# DSIG register map
Registers from a debugger description file.
Registers are 32-bit, read-only, no defined reset value unless marked. A register's access mark holds for its fields unless they carry their own. Addresses are absolute; registers are grouped by the start of their names; lines under a group give offsets from that group; [hi:lo] are bit positions; {n}, {i} and the like mark numbered series; 'fields as' and 'values as' point back to an identical list; <NAME> marks a mode.

## MUXTRIG
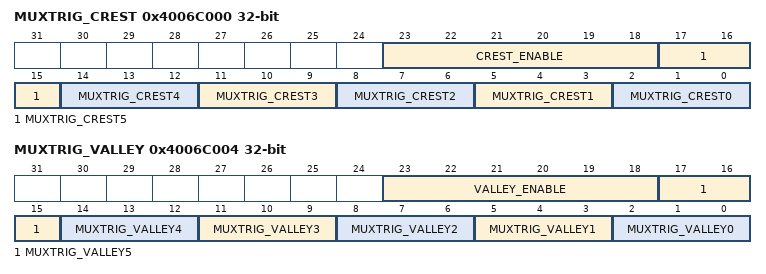
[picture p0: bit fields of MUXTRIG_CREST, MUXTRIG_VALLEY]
0x4006C000 MUXTRIG_CREST access not given
  [23:18] CREST_ENABLE, [3n+2:3n] MUXTRIG_CREST{n} (n=0..5)
0x4006C004 MUXTRIG_VALLEY access not given
  [23:18] VALLEY_ENABLE, [3n+2:3n] MUXTRIG_VALLEY{n} (n=0..5)

## CTRL
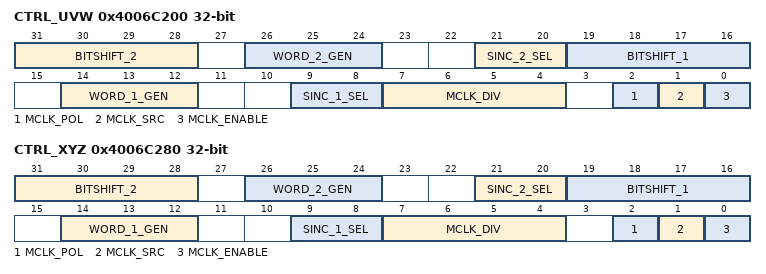
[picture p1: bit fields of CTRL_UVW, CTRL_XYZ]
0x4006C200 CTRL_UVW access not given
  [31:28] BITSHIFT_2, [26:24] WORD_2_GEN, [21:20] SINC_2_SEL, [19:16] BITSHIFT_1, [14:12] WORD_1_GEN, [9:8] SINC_1_SEL, [7:4] MCLK_DIV, [2] MCLK_POL, [1] MCLK_SRC, [0] MCLK_ENABLE
0x4006C280 CTRL_XYZ access not given
  fields as CTRL_UVW

## STATUS
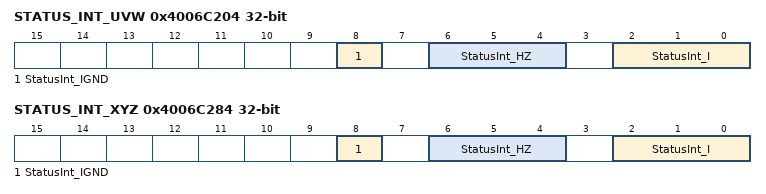
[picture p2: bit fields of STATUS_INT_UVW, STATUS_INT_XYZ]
0x4006C204 STATUS_INT_UVW access not given
  [8] StatusInt_IGND, [6:4] StatusInt_HZ, [2:0] StatusInt_I
0x4006C284 STATUS_INT_XYZ access not given
  [8] StatusInt_IGND, [6:4] StatusInt_HZ, [2:0] StatusInt_I

## CMP
0x4006C208 CMP_UVW_I_Under access not given
  [15:0] CMP_I_Under
0x4006C20C CMP_UVW_I_Over access not given
  [15:0] CMP_I_Over
0x4006C210 CMP_UVW_HZ_Under access not given
  [12:0] CMP_HZ_Under
0x4006C214 CMP_UVW_HZ_Over access not given
  [12:0] CMP_HZ_Over
0x4006C218 CMP_UVW_IGND_Under access not given
  [17:0] CMP_IGND_Under
0x4006C21C CMP_UVW_IGND_Over access not given
  [17:0] CMP_IGND_Over
0x4006C288 CMP_XYZ_I_Under access not given
  [15:0] CMP_I_Under
0x4006C28C CMP_XYZ_I_Over access not given
  [15:0] CMP_I_Over
0x4006C290 CMP_XYZ_HZ_Under access not given
  [12:0] CMP_HZ_Under
0x4006C294 CMP_XYZ_HZ_Over access not given
  [12:0] CMP_HZ_Over
0x4006C298 CMP_XYZ_IGND_Under access not given
  [17:0] CMP_IGND_Under
0x4006C29C CMP_XYZ_IGND_Over access not given
  [17:0] CMP_IGND_Over

## DATA
0x4006C220 DATA_U1
  [15:0] DATA1
0x4006C224 DATA_U1_CREST
  [15:0] DATA1_CREST
0x4006C228 DATA_U1_VALLEY
  [15:0] DATA1_VALLEY
0x4006C22C DATA_U2
  [15:0] DATA2
0x4006C230 DATA_V1
  [15:0] DATA1
0x4006C234 DATA_V1_CREST
  [15:0] DATA1_CREST
0x4006C238 DATA_V1_VALLEY
  [15:0] DATA1_VALLEY
0x4006C23C DATA_V2
  [15:0] DATA2
0x4006C240 DATA_W1
  [15:0] DATA1
0x4006C244 DATA_W1_CREST
  [15:0] DATA1_CREST
0x4006C248 DATA_W1_VALLEY
  [15:0] DATA1_VALLEY
0x4006C24C DATA_W2
  [15:0] DATA2
0x4006C2A0 DATA_X1
  [15:0] DATA1
0x4006C2A4 DATA_X1_CREST
  [15:0] DATA1_CREST
0x4006C2A8 DATA_X1_VALLEY
  [15:0] DATA1_VALLEY
0x4006C2AC DATA_X2
  [15:0] DATA2
0x4006C2B0 DATA_Y1
  [15:0] DATA1
0x4006C2B4 DATA_Y1_CREST
  [15:0] DATA1_CREST
0x4006C2B8 DATA_Y1_VALLEY
  [15:0] DATA1_VALLEY
0x4006C2BC DATA_Y2
  [15:0] DATA2
0x4006C2C0 DATA_Z1
  [15:0] DATA1
0x4006C2C4 DATA_Z1_CREST
  [15:0] DATA1_CREST
0x4006C2C8 DATA_Z1_VALLEY
  [15:0] DATA1_VALLEY
0x4006C2CC DATA_Z2
  [15:0] DATA2

## SFR
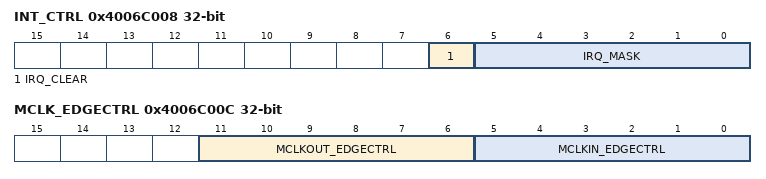
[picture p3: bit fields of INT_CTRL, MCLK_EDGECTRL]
0x4006C008 INT_CTRL access not given
  [6] IRQ_CLEAR, [5:0] IRQ_MASK
0x4006C00C MCLK_EDGECTRL access not given
  [11:6] MCLKOUT_EDGECTRL, [5:0] MCLKIN_EDGECTRL
